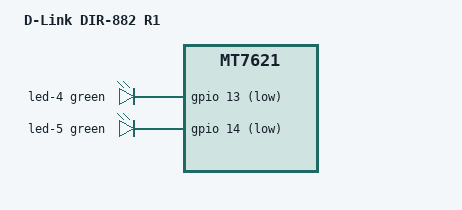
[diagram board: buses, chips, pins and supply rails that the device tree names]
// SPDX-License-Identifier: GPL-2.0-or-later OR MIT

#include "mt7621_dlink_dir-8xx.dtsi"
#include "mt7621_dlink_flash-16m-r1.dtsi"

/ {
	compatible = "dlink,dir-882-r1", "mediatek,mt7621-soc";
	model = "D-Link DIR-882 R1";
};

&leds {
	led-4 {
		function = LED_FUNCTION_USB;
		color = <LED_COLOR_ID_GREEN>;
		function-enumerator = <2>;
		gpios = <&gpio 13 GPIO_ACTIVE_LOW>;
		trigger-sources = <&ehci_port2>;
		linux,default-trigger = "usbport";
	};

	led-5 {
		function = LED_FUNCTION_USB;
		color = <LED_COLOR_ID_GREEN>;
		function-enumerator = <3>;
		gpios = <&gpio 14 GPIO_ACTIVE_LOW>;
		trigger-sources = <&xhci_ehci_port1>;
		linux,default-trigger = "usbport";
	};
};
